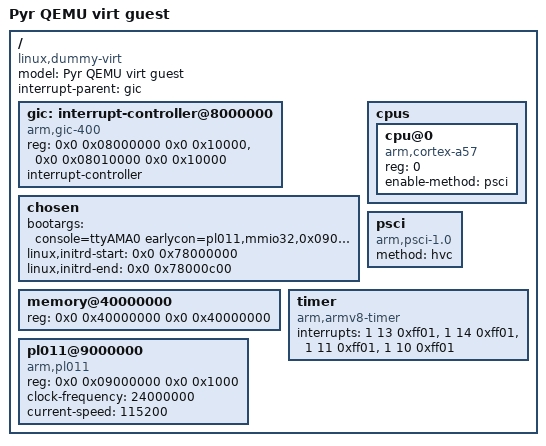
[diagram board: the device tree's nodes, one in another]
/dts-v1/;

/ {
    #address-cells = <2>;
    #size-cells = <2>;
    compatible = "linux,dummy-virt";
    model = "Pyr QEMU virt guest";
    interrupt-parent = <&gic>;

    gic: interrupt-controller@8000000 {
        compatible = "arm,gic-400";
        reg = <0x0 0x08000000 0x0 0x10000>,
              <0x0 0x08010000 0x0 0x10000>;
        interrupt-controller;
        #interrupt-cells = <3>;
    };

    chosen {
        bootargs = "console=ttyAMA0 earlycon=pl011,mmio32,0x09000000 rdinit=/init";
        linux,initrd-start = <0x0 0x78000000>;
        linux,initrd-end = <0x0 0x78000c00>;
    };

    memory@40000000 {
        device_type = "memory";
        reg = <0x0 0x40000000 0x0 0x40000000>; // 1 GiB
    };

    cpus {
        #address-cells = <1>;
        #size-cells = <0>;

        cpu@0 {
            device_type = "cpu";
            compatible = "arm,cortex-a57";
            reg = <0>;
            enable-method = "psci";
        };
    };

    psci {
        compatible = "arm,psci-1.0";
        method = "hvc";
    };

    timer {
        compatible = "arm,armv8-timer";
        interrupts = <1 13 0xff01>,
                     <1 14 0xff01>,
                     <1 11 0xff01>,
                     <1 10 0xff01>;
    };

    pl011@9000000 {
        compatible = "arm,pl011", "arm,primecell";
        reg = <0x0 0x09000000 0x0 0x1000>;
        clock-frequency = <24000000>;
        current-speed = <115200>;
        status = "okay";
    };
};
